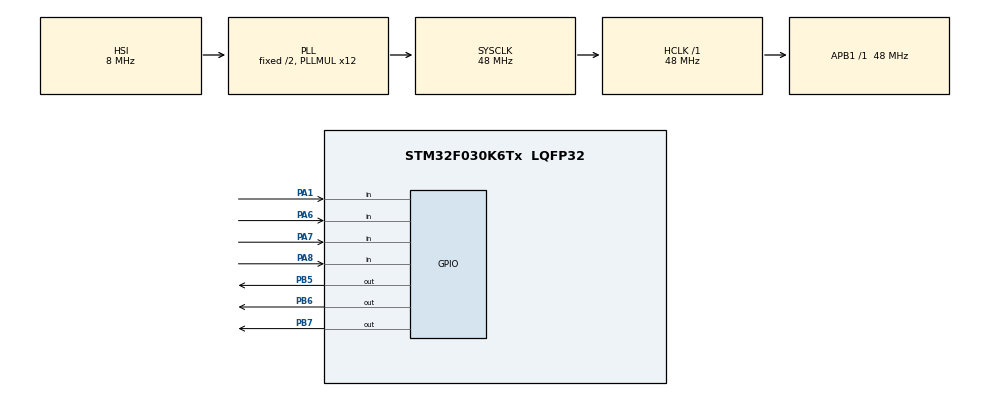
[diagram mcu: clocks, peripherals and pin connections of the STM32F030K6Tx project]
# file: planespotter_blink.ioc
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Mcu.Family=STM32F0
Mcu.Name=STM32F030K6Tx
Mcu.Package=LQFP32
PA1.Signal=GPIO_Input
PA10.Signal=USART1_RX
PA6.Signal=GPIO_Input
PA7.Signal=GPIO_Input
PA8.Signal=GPIO_Input
PA9.Signal=USART1_TX
PB5.Signal=GPIO_Output
PB6.Signal=GPIO_Output
PB7.Signal=GPIO_Output
ProjectManager.HeapSize=0x200
ProjectManager.StackSize=0x400
ProjectManager.TargetToolchain=STM32CubeIDE
RCC.AHBFreq_Value=48000000
RCC.APB1Freq_Value=48000000
RCC.APB1TimFreq_Value=48000000
RCC.HCLKFreq_Value=48000000
RCC.PLLMUL=RCC_PLL_MUL12
RCC.SYSCLKFreq_VALUE=48000000
RCC.SYSCLKSource=RCC_SYSCLKSOURCE_PLLCLK
board=custom

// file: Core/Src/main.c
/* USER CODE BEGIN Header */
/**
  ******************************************************************************
  * @file           : main.c
  * @brief          : Main program body
  ******************************************************************************
  * @attention
  *
  * Copyright (c) 2024 STMicroelectronics.
  * All rights reserved.
  *
  * This software is licensed under terms that can be found in the LICENSE file
  * in the root directory of this software component.
  * If no LICENSE file comes with this software, it is provided AS-IS.
  *
  ******************************************************************************
  */
/* USER CODE END Header */
#include "main.h"

void SystemClock_Config(void);
static void MX_GPIO_Init(void);

int main(void)
{

  /* USER CODE BEGIN 1 */

  char ledState1 = 1;
  char ledState2 = 0;
  char ledState3 = 1;

  /* USER CODE END 1 */

  /* MCU Configuration--------------------------------------------------------*/

  /* Reset of all peripherals, Initializes the Flash interface and the Systick. */
  HAL_Init();

  /* Configure the system clock */
  SystemClock_Config();

  /* Initialize all configured peripherals */
  MX_GPIO_Init();
  /* USER CODE BEGIN 2 */

  HAL_GPIO_WritePin(GPIOB, GPIO_PIN_5, ledState1);
  HAL_GPIO_WritePin(GPIOB, GPIO_PIN_6, ledState2);
  HAL_GPIO_WritePin(GPIOB, GPIO_PIN_7, ledState3);

  /* USER CODE END 2 */

  /* Infinite loop */
  while (1)
  {

    /* USER CODE BEGIN 3 */
	ledState1 = 1 - ledState1;
	ledState2 = 1 - ledState2;
	ledState3 = 1 - ledState3;
	HAL_GPIO_WritePin(GPIOB, GPIO_PIN_5, ledState1);
	HAL_GPIO_WritePin(GPIOB, GPIO_PIN_6, ledState2);
	HAL_GPIO_WritePin(GPIOB, GPIO_PIN_7, ledState3);
	HAL_Delay(250);
  }
  /* USER CODE END 3 */
}

void SystemClock_Config(void)
{
  RCC_OscInitTypeDef RCC_OscInitStruct = {0};
  RCC_ClkInitTypeDef RCC_ClkInitStruct = {0};

  /** Initializes the RCC Oscillators according to the specified parameters
  * in the RCC_OscInitTypeDef structure.
  */
  RCC_OscInitStruct.OscillatorType = RCC_OSCILLATORTYPE_HSI;
  RCC_OscInitStruct.HSIState = RCC_HSI_ON;
  RCC_OscInitStruct.HSICalibrationValue = RCC_HSICALIBRATION_DEFAULT;
  RCC_OscInitStruct.PLL.PLLState = RCC_PLL_ON;
  RCC_OscInitStruct.PLL.PLLSource = RCC_PLLSOURCE_HSI;
  RCC_OscInitStruct.PLL.PLLMUL = RCC_PLL_MUL12;
  RCC_OscInitStruct.PLL.PREDIV = RCC_PREDIV_DIV1;
  if (HAL_RCC_OscConfig(&RCC_OscInitStruct) != HAL_OK)
  {
    Error_Handler();
  }

  /** Initializes the CPU, AHB and APB buses clocks
  */
  RCC_ClkInitStruct.ClockType = RCC_CLOCKTYPE_HCLK|RCC_CLOCKTYPE_SYSCLK
                              |RCC_CLOCKTYPE_PCLK1;
  RCC_ClkInitStruct.SYSCLKSource = RCC_SYSCLKSOURCE_PLLCLK;
  RCC_ClkInitStruct.AHBCLKDivider = RCC_SYSCLK_DIV1;
  RCC_ClkInitStruct.APB1CLKDivider = RCC_HCLK_DIV1;

  if (HAL_RCC_ClockConfig(&RCC_ClkInitStruct, FLASH_LATENCY_1) != HAL_OK)
  {
    Error_Handler();
  }
}

static void MX_GPIO_Init(void)
{
  GPIO_InitTypeDef GPIO_InitStruct = {0};

  /* GPIO Ports Clock Enable */
  __HAL_RCC_GPIOA_CLK_ENABLE();
  __HAL_RCC_GPIOB_CLK_ENABLE();

  /*Configure GPIO pin Output Level */
  HAL_GPIO_WritePin(GPIOB, GPIO_PIN_5|GPIO_PIN_6|GPIO_PIN_7, GPIO_PIN_RESET);

  /*Configure GPIO pins : PA1 PA6 PA7 PA8 */
  GPIO_InitStruct.Pin = GPIO_PIN_1|GPIO_PIN_6|GPIO_PIN_7|GPIO_PIN_8;
  GPIO_InitStruct.Mode = GPIO_MODE_INPUT;
  GPIO_InitStruct.Pull = GPIO_NOPULL;
  HAL_GPIO_Init(GPIOA, &GPIO_InitStruct);

  /*Configure GPIO pins : PA9 PA10 */
  GPIO_InitStruct.Pin = GPIO_PIN_9|GPIO_PIN_10;
  GPIO_InitStruct.Mode = GPIO_MODE_AF_PP;
  GPIO_InitStruct.Pull = GPIO_NOPULL;
  GPIO_InitStruct.Speed = GPIO_SPEED_FREQ_HIGH;
  GPIO_InitStruct.Alternate = GPIO_AF1_USART1;
  HAL_GPIO_Init(GPIOA, &GPIO_InitStruct);

  /*Configure GPIO pins : PB5 PB6 PB7 */
  GPIO_InitStruct.Pin = GPIO_PIN_5|GPIO_PIN_6|GPIO_PIN_7;
  GPIO_InitStruct.Mode = GPIO_MODE_OUTPUT_PP;
  GPIO_InitStruct.Pull = GPIO_NOPULL;
  GPIO_InitStruct.Speed = GPIO_SPEED_FREQ_LOW;
  HAL_GPIO_Init(GPIOB, &GPIO_InitStruct);

}

void Error_Handler(void)
{
  __disable_irq();
  while (1)
  {
  }
}
